VERSION ""

NS_ :

BS_:

BU_: BMS Inverter IMD FrontECU RearECU HVAB HVDB TSAL SDC

BO_ 3221225472 VECTOR__INDEPENDENT_SIG_MSG: 0 Vector__XXX
 SG_ FpANLLpot : 0|16@1- (1,0) [-32768|32767] "" Vector__XXX
 SG_ FpINTpre : 0|1@1+ (1,0) [0|1] "" Vector__XXX
 SG_ SpERRbms : 0|1@1+ (1,0) [0|1] "" Vector__XXX
 SG_ SpERRbimd : 0|1@1+ (1,0) [0|1] "" Vector__XXX

BO_ 0 New_Message_19: 8 Vector__XXX
 SG_ New_Signal_111 : 32|8@1+ (1,0) [0|0] "" Vector__XXX

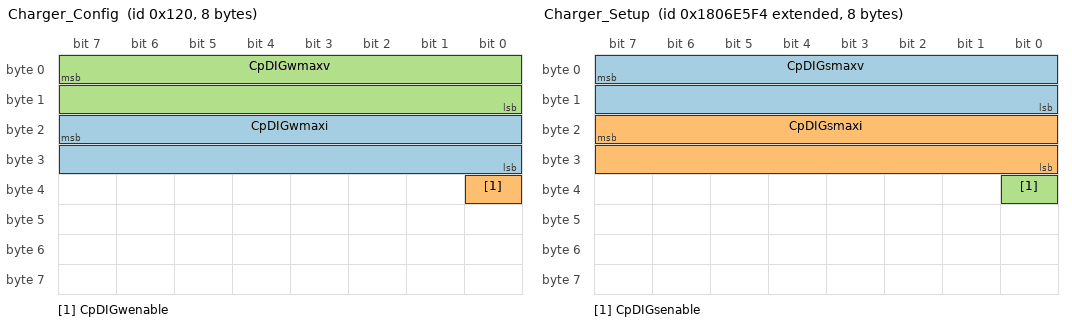
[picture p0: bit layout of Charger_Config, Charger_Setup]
BO_ 288 Charger_Config: 8 Vector__XXX
 SG_ CpDIGwmaxi : 23|16@0+ (0.1,0) [0|6553.5] "A" Vector__XXX
 SG_ CpDIGwenable : 32|1@0+ (1,0) [0|1] "" Vector__XXX
 SG_ CpDIGwmaxv : 7|16@0+ (0.1,0) [0|6553.5] "V" Vector__XXX

BO_ 2550588916 Charger_Setup: 8 Vector__XXX
 SG_ CpDIGsmaxv : 7|16@0+ (0.1,0) [0|6553.5] "V" Vector__XXX
 SG_ CpDIGsmaxi : 23|16@0+ (0.1,0) [0|6553.5] "A" Vector__XXX
 SG_ CpDIGsenable : 32|1@0+ (1,0) [0|1] "" Vector__XXX

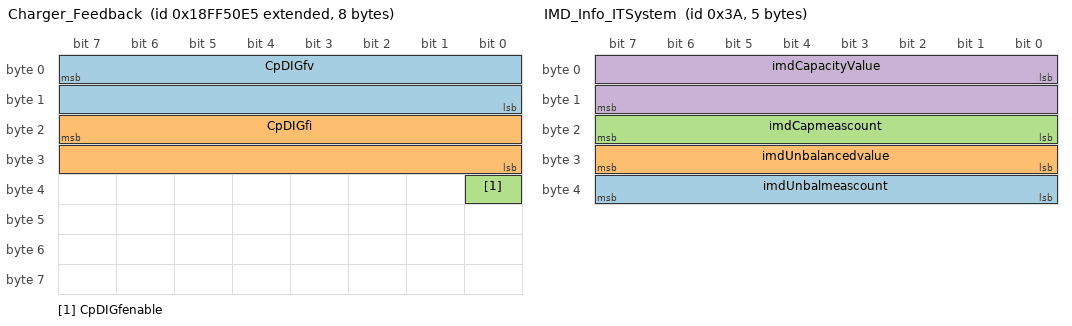
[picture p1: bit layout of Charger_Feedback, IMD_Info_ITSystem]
BO_ 2566869221 Charger_Feedback: 8 Vector__XXX
 SG_ CpDIGfv : 7|16@0+ (0.1,0) [0|6553.5] "V" Vector__XXX
 SG_ CpDIGfi : 23|16@0+ (0.1,0) [0|6553.5] "A" Vector__XXX
 SG_ CpDIGfenable : 32|1@0+ (1,0) [0|1] "" Vector__XXX

BO_ 259 InverterTX: 8 Inverter
 SG_ iWarn m143 : 24|16@1+ (1,0) [0|65535] "" Vector__XXX
 SG_ iVout m138 : 8|16@1+ (1,0) [0|4000] "" Vector__XXX
 SG_ iTmot m73 : 8|16@1+ (1,0) [0|32767] "" Vector__XXX
 SG_ iTinv m74 : 8|16@1+ (1,0) [0|32767] "" Vector__XXX
 SG_ iRPM m48 : 8|16@1+ (1,0) [0|32767] "" Vector__XXX
 SG_ iPar m160 : 8|16@1- (1,0) [-32768|32767] "" Vector__XXX
 SG_ iIout m72 : 8|16@1+ (1,0) [0|2000] "" Vector__XXX
 SG_ iErr m143 : 8|16@1+ (1,0) [0|65535] "" Vector__XXX
 SG_ RegID M : 0|8@1+ (1,0) [0|255] "" Vector__XXX

BO_ 58 IMD_Info_ITSystem: 5 IMD
 SG_ imdUnbalmeascount : 32|8@1+ (1,0) [0|255] "" Vector__XXX
 SG_ imdUnbalancedvalue : 24|8@1+ (1,0) [0|100] "%" Vector__XXX
 SG_ imdCapmeascount : 16|8@1+ (1,0) [0|255] "" Vector__XXX
 SG_ imdCapacityValue : 0|16@1+ (0.1,0) [0|6553.5] "uF" Vector__XXX

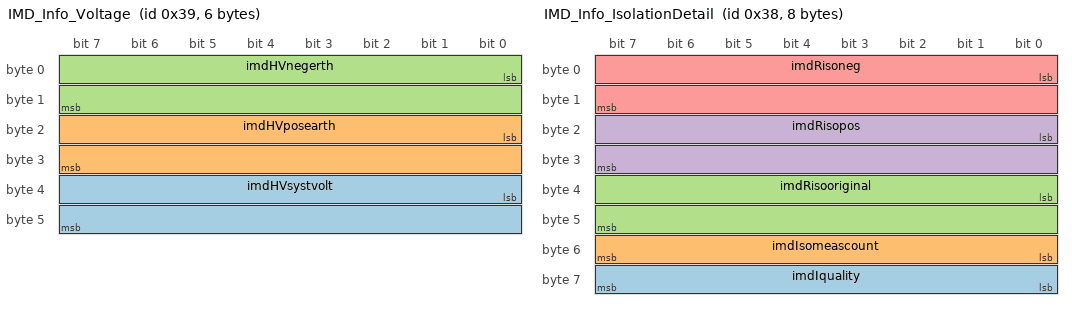
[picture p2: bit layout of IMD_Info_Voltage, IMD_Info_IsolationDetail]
BO_ 57 IMD_Info_Voltage: 6 IMD
 SG_ imdHVsystvolt : 32|16@1+ (0.05,-1606.4) [-1606.4|1670.35] "V" Vector__XXX
 SG_ imdHVposearth : 16|16@1+ (0.05,-1606.4) [-1606.4|1670.35] "V" Vector__XXX
 SG_ imdHVnegerth : 0|16@1+ (0.05,-1606.4) [-1606.4|1670.35] "V" Vector__XXX

BO_ 56 IMD_Info_IsolationDetail: 8 IMD
 SG_ imdIquality : 56|8@1+ (1,0) [0|100] "%" Vector__XXX
 SG_ imdIsomeascount : 48|8@1+ (1,0) [0|255] "" Vector__XXX
 SG_ imdRisooriginal : 32|16@1+ (1,0) [0|65535] "kOhm" Vector__XXX
 SG_ imdRisopos : 16|16@1+ (1,0) [0|65535] "kOhm" Vector__XXX
 SG_ imdRisoneg : 0|16@1+ (1,0) [0|65535] "kOhm" Vector__XXX

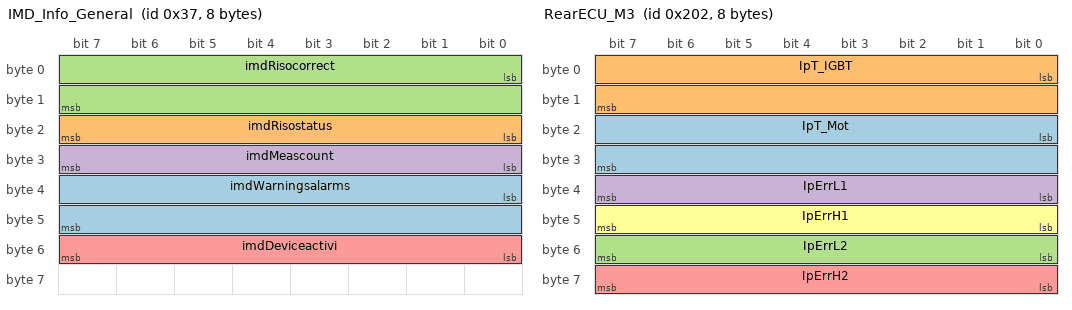
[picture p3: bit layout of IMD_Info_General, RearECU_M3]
BO_ 55 IMD_Info_General: 8 IMD
 SG_ imdWarningsalarms : 32|16@1+ (1,0) [0|65535] "" Vector__XXX
 SG_ imdRisostatus : 16|8@1+ (1,0) [0|255] "" Vector__XXX
 SG_ imdRisocorrect : 0|16@1+ (1,0) [0|65535] "" Vector__XXX
 SG_ imdMeascount : 24|8@1+ (1,0) [0|255] "" Vector__XXX
 SG_ imdDeviceactivi : 48|8@1+ (1,0) [0|255] "" Vector__XXX

BO_ 258 InverterRX: 8 Inverter
 SG_ FpANLRpot : 8|16@1- (1,0) [-32768|32767] "" Vector__XXX

BO_ 514 RearECU_M3: 8 RearECU
 SG_ IpT_Mot : 16|16@1+ (1,0) [0|65535] ""  RearECU
 SG_ IpT_IGBT : 0|16@1+ (1,0) [0|65535] ""  RearECU
 SG_ IpErrL2 : 48|8@1+ (1,0) [0|255] ""  RearECU
 SG_ IpErrL1 : 32|8@1+ (1,0) [0|255] ""  RearECU
 SG_ IpErrH2 : 56|8@1+ (1,0) [0|255] ""  RearECU
 SG_ IpErrH1 : 40|8@1+ (1,0) [0|255] ""  RearECU

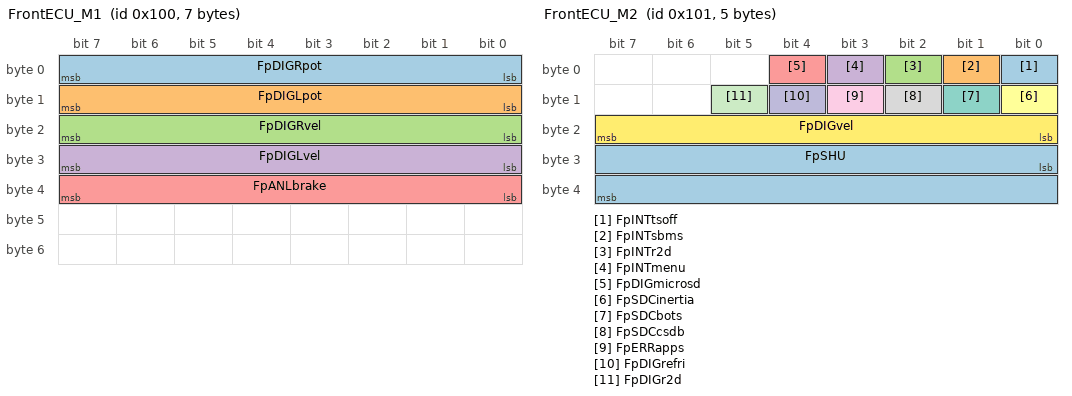
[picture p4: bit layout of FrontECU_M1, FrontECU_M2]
BO_ 256 FrontECU_M1: 7 FrontECU
 SG_ FpDIGRpot : 0|8@1+ (0.392157,0) [0|100] "%" Vector__XXX
 SG_ FpDIGLpot : 8|8@1+ (0.392157,0) [0|100] "%" Vector__XXX
 SG_ FpDIGRvel : 16|8@1+ (1,0) [0|255] "km/h"  FrontECU
 SG_ FpDIGLvel : 24|8@1+ (1,0) [0|255] "km/h"  FrontECU
 SG_ FpANLbrake : 32|8@1+ (0.27451,0) [0|70] "MPa"  FrontECU

BO_ 257 FrontECU_M2: 5 FrontECU
 SG_ FpINTtsoff : 0|1@1+ (1,0) [0|1] ""  FrontECU
 SG_ FpINTsbms : 1|1@1+ (1,0) [0|1] ""  FrontECU
 SG_ FpINTr2d : 2|1@1+ (1,0) [0|1] ""  FrontECU
 SG_ FpINTmenu : 3|1@1+ (1,0) [0|1] ""  FrontECU
 SG_ FpDIGmicrosd : 4|1@1+ (1,0) [0|1] ""  FrontECU
 SG_ FpSDCinertia : 8|1@1+ (1,0) [0|1] ""  FrontECU
 SG_ FpSDCbots : 9|1@1+ (1,0) [0|1] ""  FrontECU
 SG_ FpSDCcsdb : 10|1@1+ (1,0) [0|1] ""  FrontECU
 SG_ FpERRapps : 11|1@1+ (1,0) [0|1] ""  FrontECU
 SG_ FpDIGrefri : 12|1@1+ (1,0) [0|1] ""  FrontECU
 SG_ FpDIGr2d : 13|1@1+ (1,0) [0|1] ""  FrontECU
 SG_ FpDIGvel : 16|8@1+ (1,0) [0|255] "km/h"  FrontECU
 SG_ FpSHU : 24|16@1+ (1,0) [0|5000] "mA"  FrontECU

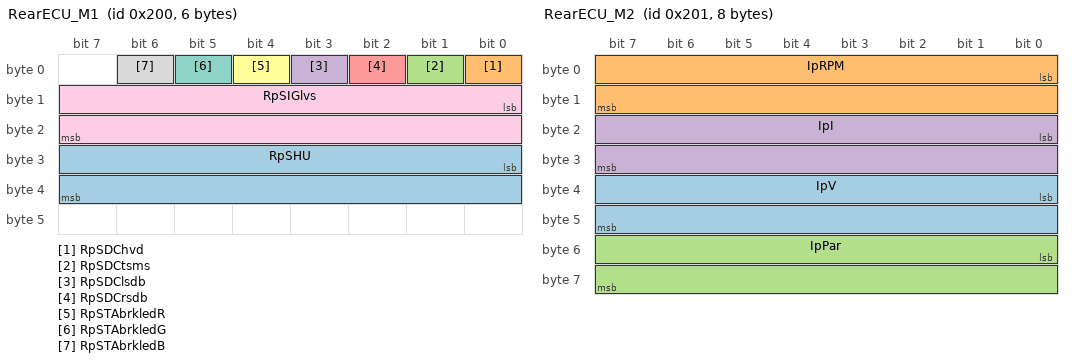
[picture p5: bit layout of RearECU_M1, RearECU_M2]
BO_ 512 RearECU_M1: 6 RearECU
 SG_ RpSHU : 24|16@1+ (1,0) [0|5000] "mA"  RearECU
 SG_ RpSDChvd : 0|1@1+ (1,0) [0|1] "mm"  RearECU
 SG_ RpSDCtsms : 1|1@1+ (1,0) [0|1] "mm"  RearECU
 SG_ RpSDClsdb : 3|1@1+ (1,0) [0|1] "km/h"  RearECU
 SG_ RpSDCrsdb : 2|1@1+ (1,0) [0|1] "km/h"  RearECU
 SG_ RpSTAbrkledR : 4|1@1+ (1,0) [0|1] "degC"  RearECU
 SG_ RpSTAbrkledG : 5|1@1+ (1,0) [0|1] "degC"  RearECU
 SG_ RpSTAbrkledB : 6|1@1+ (1,0) [0|1] "degC"  RearECU
 SG_ RpSIGlvs : 8|16@1+ (1,0) [0|65535] "degC"  RearECU

BO_ 513 RearECU_M2: 8 RearECU
 SG_ IpV : 32|16@1+ (1,0) [0|65535] ""  RearECU
 SG_ IpRPM : 0|16@1+ (1,0) [0|65535] ""  RearECU
 SG_ IpPar : 48|16@1+ (1,0) [0|65535] ""  RearECU
 SG_ IpI : 16|16@1+ (1,0) [0|65535] ""  RearECU

BO_ 768 HVAB: 3 HVAB
 SG_ ApTHRhv : 0|1@1+ (1,0) [0|1] ""  HVAB
 SG_ ApSHU : 8|16@1+ (1,0) [0|5000] "mA"  HVAB

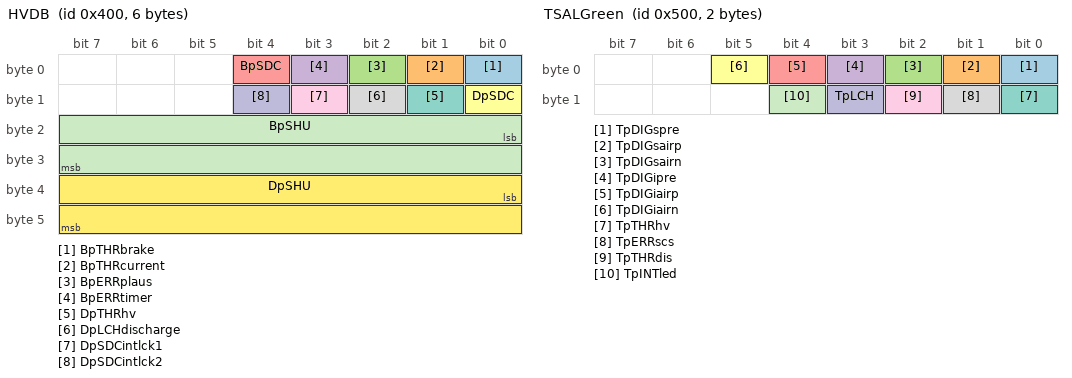
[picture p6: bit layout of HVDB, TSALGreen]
BO_ 1024 HVDB: 6 HVDB
 SG_ BpTHRbrake : 0|1@1+ (1,0) [0|1] ""  HVDB
 SG_ BpTHRcurrent : 1|1@1+ (1,0) [0|1] ""  HVDB
 SG_ BpERRplaus : 2|1@1+ (1,0) [0|1] ""  HVDB
 SG_ BpERRtimer : 3|1@1+ (1,0) [0|1] ""  HVDB
 SG_ BpSDC : 4|1@1+ (1,0) [0|1] ""  HVDB
 SG_ DpSDC : 8|1@1+ (1,0) [0|1] ""  HVDB
 SG_ DpTHRhv : 9|1@1+ (1,0) [0|1] ""  HVDB
 SG_ DpLCHdischarge : 10|1@1+ (1,0) [0|1] ""  HVDB
 SG_ DpSDCintlck1 : 11|1@1+ (1,0) [0|1] ""  HVDB
 SG_ DpSDCintlck2 : 12|1@1+ (1,0) [0|1] ""  HVDB
 SG_ BpSHU : 16|16@1+ (1,0) [0|5000] "mA"  HVDB
 SG_ DpSHU : 32|16@1+ (1,0) [0|5000] "mA"  HVDB

BO_ 1280 TSALGreen: 2 TSAL
 SG_ TpDIGspre : 0|1@1+ (1,0) [0|1] ""  TSAL
 SG_ TpDIGsairp : 1|1@1+ (1,0) [0|1] ""  TSAL
 SG_ TpDIGsairn : 2|1@1+ (1,0) [0|1] ""  TSAL
 SG_ TpDIGipre : 3|1@1+ (1,0) [0|1] ""  TSAL
 SG_ TpDIGiairp : 4|1@1+ (1,0) [0|1] ""  TSAL
 SG_ TpDIGiairn : 5|1@1+ (1,0) [0|1] ""  TSAL
 SG_ TpTHRhv : 8|1@1+ (1,0) [0|1] ""  TSAL
 SG_ TpERRscs : 9|1@1+ (1,0) [0|1] ""  TSAL
 SG_ TpTHRdis : 10|1@1+ (1,0) [0|1] ""  TSAL
 SG_ TpLCH : 11|1@1+ (1,0) [0|1] ""  TSAL
 SG_ TpINTled : 12|1@1+ (1,0) [0|1] ""  TSAL

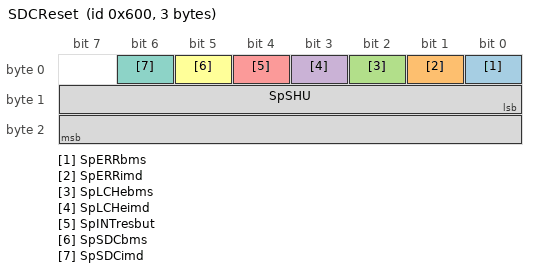
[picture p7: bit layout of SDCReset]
BO_ 1536 SDCReset: 3 SDC
 SG_ SpERRbms : 0|1@1+ (1,0) [0|1] ""  SDC
 SG_ SpERRimd : 1|1@1+ (1,0) [0|1] ""  SDC
 SG_ SpLCHebms : 2|1@1+ (1,0) [0|1] ""  SDC
 SG_ SpLCHeimd : 3|1@1+ (1,0) [0|1] ""  SDC
 SG_ SpINTresbut : 4|1@1+ (1,0) [0|1] ""  SDC
 SG_ SpSDCbms : 5|1@1+ (1,0) [0|1] ""  SDC
 SG_ SpSDCimd : 6|1@1+ (1,0) [0|1] ""  SDC
 SG_ SpSHU : 8|16@1+ (1,0) [0|5000] "mA"  SDC

CM_ BO_ 3221225472 "This is a message for not used signals, created by Vector CANdb++ DBC OLE DB Provider.";
BA_DEF_ BO_  "VFrameFormat" ENUM  "StandardCAN","ExtendedCAN","reserved","reserved","reserved","reserved","reserved","reserved","reserved","reserved","reserved","reserved","reserved","reserved","StandardCAN_FD","ExtendedCAN_FD","J1939PGN";
BA_DEF_ BO_  "SendMode" ENUM  "Cyclic","IfActive","NoMsgSendType";
BA_DEF_ BU_  "NodeAddress" INT 0 255;
BA_DEF_  "MultiplexExtEnabled" ENUM  "No","Yes";
BA_DEF_  "BusType" STRING ;
BA_DEF_DEF_  "VFrameFormat" "J1939PGN";
BA_DEF_DEF_  "SendMode" "Cyclic";
BA_DEF_DEF_  "NodeAddress" 254;
BA_DEF_DEF_  "MultiplexExtEnabled" "Yes";
BA_DEF_DEF_  "BusType" "J1939";
BA_ "VFrameFormat" BO_ 288 0;
BA_ "VFrameFormat" BO_ 2550588916 1;
BA_ "VFrameFormat" BO_ 2566869221 1;
